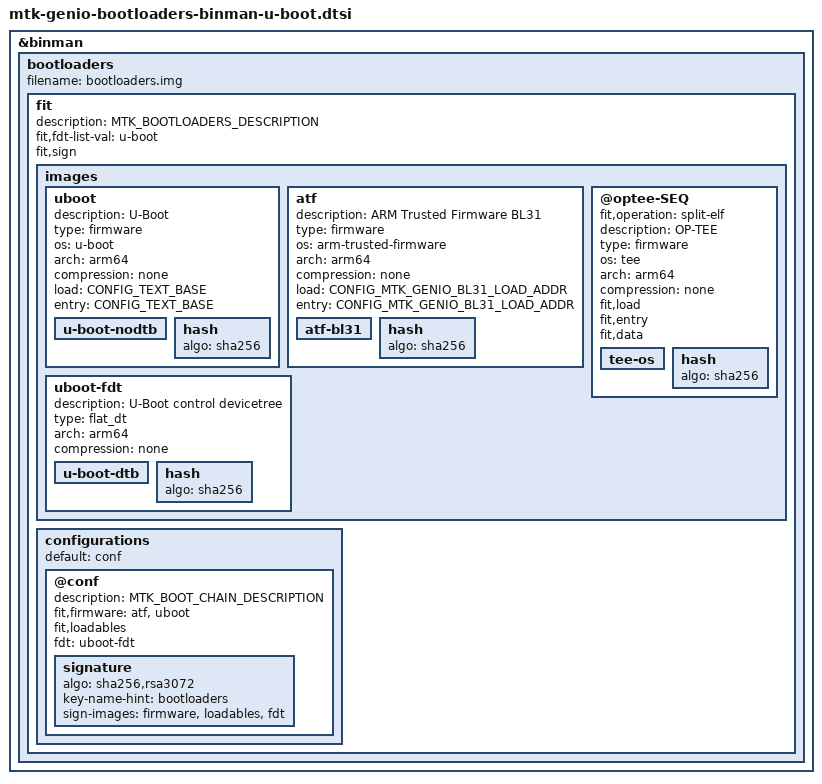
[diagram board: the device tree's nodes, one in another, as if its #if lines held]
// SPDX-License-Identifier: (GPL-2.0-only OR MIT)
/*
 * Copyright (c) 2026 BayLibre SAS
 * Author: Julien Stephan <jstephan@baylibre.com>
 * Author: Carlo Caione <ccaione@baylibre.com>
 */

&binman {
	bootloaders {
		filename = "bootloaders.img";

		fit {
			description = MTK_BOOTLOADERS_DESCRIPTION;
			#address-cells = <1>;
			fit,fdt-list-val = "u-boot";
#ifdef CONFIG_SPL_FIT_SIGNATURE
			fit,sign;
#endif

			images {
				uboot {
					description = "U-Boot";
					type = "firmware";
					os = "u-boot";
					arch = "arm64";
					compression = "none";
					load = <CONFIG_TEXT_BASE>;
					entry = <CONFIG_TEXT_BASE>;

					u-boot-nodtb {
					};

					hash {
						algo = "sha256";
					};
				};

				atf {
					description = "ARM Trusted Firmware BL31";
					type = "firmware";
					os = "arm-trusted-firmware";
					arch = "arm64";
					compression = "none";
					load = <CONFIG_MTK_GENIO_BL31_LOAD_ADDR>;
					entry = <CONFIG_MTK_GENIO_BL31_LOAD_ADDR>;

					atf-bl31 {
					};

					hash {
						algo = "sha256";
					};
				};

				@optee-SEQ {
					fit,operation = "split-elf";
					description = "OP-TEE";
					type = "firmware";
					os = "tee";
					arch = "arm64";
					compression = "none";
					fit,load;
					fit,entry;
					fit,data;

					tee-os {
					};

					hash {
						algo = "sha256";
					};
				};

				uboot-fdt {
					description = "U-Boot control devicetree";
					type = "flat_dt";
					arch = "arm64";
					compression = "none";

					u-boot-dtb {
					};

					hash {
						algo = "sha256";
					};
				};
			};

			configurations {
				default = "conf";

				@conf {
					description = MTK_BOOT_CHAIN_DESCRIPTION;
					fit,firmware = "atf", "uboot";
					fit,loadables;
					fdt = "uboot-fdt";
#ifdef CONFIG_SPL_FIT_SIGNATURE

					signature {
						algo = "sha256,rsa3072";
						key-name-hint = "bootloaders";
						sign-images = "firmware", "loadables", "fdt";
					};
#endif
				};
			};
		};
	};
};
